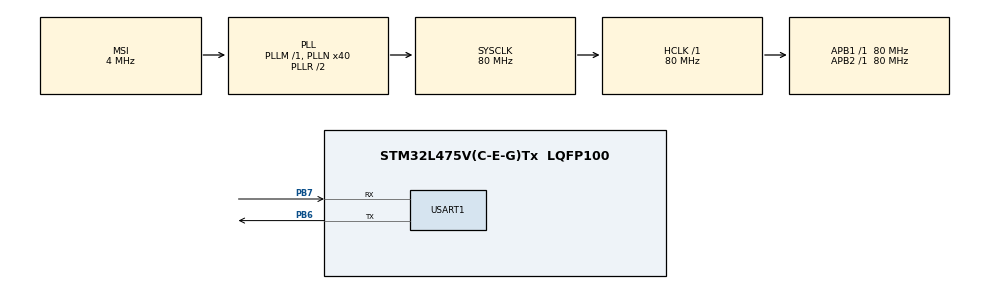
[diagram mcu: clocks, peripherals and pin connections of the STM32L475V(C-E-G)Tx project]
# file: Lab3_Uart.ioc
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ADC1.Channel-0\#ChannelRegularConversion=ADC_CHANNEL_TEMPSENSOR
ADC1.ClockPrescaler=ADC_CLOCK_ASYNC_DIV1
ADC1.ContinuousConvMode=DISABLE
ADC1.DMAContinuousRequests=DISABLE
ADC1.DataAlign=ADC_DATAALIGN_RIGHT
ADC1.DiscontinuousConvMode=DISABLE
ADC1.EOCSelection=ADC_EOC_SINGLE_CONV
ADC1.EnableAnalogWatchDog1=false
ADC1.EnableAnalogWatchDog2=false
ADC1.EnableAnalogWatchDog3=false
ADC1.EnableInjectedConversion=DISABLE
ADC1.EnableRegularConversion=ENABLE
ADC1.ExternalTrigConv=ADC_SOFTWARE_START
ADC1.ExternalTrigConvEdge=ADC_EXTERNALTRIGCONVEDGE_NONE
ADC1.LowPowerAutoWait=DISABLE
ADC1.NbrOfConversion=1
ADC1.NbrOfConversionFlag=1
ADC1.OffsetNumber-0\#ChannelRegularConversion=ADC_OFFSET_NONE
ADC1.Overrun=ADC_OVR_DATA_PRESERVED
ADC1.OversamplingMode=DISABLE
ADC1.Rank-0\#ChannelRegularConversion=1
ADC1.Resolution=ADC_RESOLUTION_10B
ADC1.SamplingTime-0\#ChannelRegularConversion=ADC_SAMPLETIME_2CYCLES_5
ADC1.ScanConvMode=ADC_SCAN_DISABLE
ADC1.master=1
Dma.Request0=USART1_RX
Dma.Request1=USART1_TX
Dma.USART1_RX.0.Direction=DMA_PERIPH_TO_MEMORY
Dma.USART1_RX.0.Instance=DMA1_Channel5
Dma.USART1_RX.0.MemDataAlignment=DMA_MDATAALIGN_HALFWORD
Dma.USART1_RX.0.MemInc=DMA_MINC_ENABLE
Dma.USART1_RX.0.Mode=DMA_NORMAL
Dma.USART1_RX.0.PeriphDataAlignment=DMA_PDATAALIGN_HALFWORD
Dma.USART1_RX.0.PeriphInc=DMA_PINC_DISABLE
Dma.USART1_RX.0.Priority=DMA_PRIORITY_LOW
Dma.USART1_TX.1.Direction=DMA_MEMORY_TO_PERIPH
Dma.USART1_TX.1.Instance=DMA1_Channel4
Dma.USART1_TX.1.MemDataAlignment=DMA_MDATAALIGN_HALFWORD
Dma.USART1_TX.1.MemInc=DMA_MINC_ENABLE
Dma.USART1_TX.1.Mode=DMA_NORMAL
Dma.USART1_TX.1.PeriphDataAlignment=DMA_PDATAALIGN_HALFWORD
Dma.USART1_TX.1.PeriphInc=DMA_PINC_DISABLE
Dma.USART1_TX.1.Priority=DMA_PRIORITY_LOW
Mcu.Family=STM32L4
Mcu.Name=STM32L475V(C-E-G)Tx
Mcu.Package=LQFP100
NVIC.DMA1_Channel4_IRQn=true\:0\:0\:false\:false\:true\:false
NVIC.DMA1_Channel5_IRQn=true\:0\:0\:false\:false\:true\:false
NVIC.PriorityGroup=NVIC_PRIORITYGROUP_4
NVIC.USART1_IRQn=true\:0\:0\:false\:false\:true\:true
PB6.Mode=Asynchronous
PB6.Signal=USART1_TX
PB7.Mode=Asynchronous
PB7.Signal=USART1_RX
ProjectManager.HeapSize=0x200
ProjectManager.StackSize=0x400
ProjectManager.TargetToolchain=MDK-ARM V5
RCC.ADCFreq_Value=64000000
RCC.AHBFreq_Value=80000000
RCC.APB1Freq_Value=80000000
RCC.APB1TimFreq_Value=80000000
RCC.APB2Freq_Value=80000000
RCC.APB2TimFreq_Value=80000000
RCC.CortexFreq_Value=80000000
RCC.HCLKFreq_Value=80000000
RCC.HSE_VALUE=8000000
RCC.HSI_VALUE=16000000
RCC.LSE_VALUE=32768
RCC.MSI_VALUE=4000000
RCC.PLLN=40
RCC.PLLSAI1N=32
RCC.SYSCLKFreq_VALUE=80000000
RCC.SYSCLKSource=RCC_SYSCLKSOURCE_PLLCLK
RCC.USBFreq_Value=64000000
RCC.VCOOutputFreq_Value=160000000
USART1.VirtualMode-Asynchronous=VM_ASYNC
USART1.WordLength=WORDLENGTH_8B
VP_ADC1_TempSens_Input.Mode=IN-TempSens
board=Lab3_Uart

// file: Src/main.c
/**
  ******************************************************************************
  * @file           : main.c
  * @brief          : Main program body
  ******************************************************************************
  ** This notice applies to any and all portions of this file
  * that are not between comment pairs USER CODE BEGIN and
  * USER CODE END. Other portions of this file, whether
  * inserted by the user or by software development tools
  * are owned by their respective copyright owners.
  *
  * COPYRIGHT(c) 2018 STMicroelectronics
  *
  * Redistribution and use in source and binary forms, with or without modification,
  * are permitted provided that the following conditions are met:
  *   1. Redistributions of source code must retain the above copyright notice,
  *      this list of conditions and the following disclaimer.
  *   2. Redistributions in binary form must reproduce the above copyright notice,
  *      this list of conditions and the following disclaimer in the documentation
  *      and/or other materials provided with the distribution.
  *   3. Neither the name of STMicroelectronics nor the names of its contributors
  *      may be used to endorse or promote products derived from this software
  *      without specific prior written permission.
  *
  * THIS SOFTWARE IS PROVIDED BY THE COPYRIGHT HOLDERS AND CONTRIBUTORS "AS IS"
  * AND ANY EXPRESS OR IMPLIED WARRANTIES, INCLUDING, BUT NOT LIMITED TO, THE
  * IMPLIED WARRANTIES OF MERCHANTABILITY AND FITNESS FOR A PARTICULAR PURPOSE ARE
  * DISCLAIMED. IN NO EVENT SHALL THE COPYRIGHT HOLDER OR CONTRIBUTORS BE LIABLE
  * FOR ANY DIRECT, INDIRECT, INCIDENTAL, SPECIAL, EXEMPLARY, OR CONSEQUENTIAL
  * DAMAGES (INCLUDING, BUT NOT LIMITED TO, PROCUREMENT OF SUBSTITUTE GOODS OR
  * SERVICES; LOSS OF USE, DATA, OR PROFITS; OR BUSINESS INTERRUPTION) HOWEVER
  * CAUSED AND ON ANY THEORY OF LIABILITY, WHETHER IN CONTRACT, STRICT LIABILITY,
  * OR TORT (INCLUDING NEGLIGENCE OR OTHERWISE) ARISING IN ANY WAY OUT OF THE USE
  * OF THIS SOFTWARE, EVEN IF ADVISED OF THE POSSIBILITY OF SUCH DAMAGE.
  *
  ******************************************************************************
  */
#include "main.h"
#include "stm32l4xx_hal.h"

ADC_HandleTypeDef hadc1;

UART_HandleTypeDef huart1;
DMA_HandleTypeDef hdma_usart1_rx;
DMA_HandleTypeDef hdma_usart1_tx;

/* USER CODE BEGIN PV */
/* Private variables ---------------------------------------------------------*/
	const int size = 7;
	char string[size] = {'s','t','a','r','t','\r','\n'};
	char input[1];
  char response[1] = {'y'};
  char ch[15] = {'j','o','b','s','\n', 'j','o','b','s','\n', 'j','o','b','s','\n'};
	char ADCValues[15];
	int ADCIndex = 0;
	int flag = 0;
	int txDone = 1;
	int temp = 0;
/* USER CODE END PV */

void SystemClock_Config(void);
static void MX_GPIO_Init(void);
static void MX_DMA_Init(void);
static void MX_ADC1_Init(void);
static void MX_USART1_UART_Init(void);

/* USER CODE BEGIN PFP */
/* Private function prototypes -----------------------------------------------*/

/* USER CODE END PFP */

/* USER CODE BEGIN 0 */
void ADC_Poll(void) {
	HAL_ADC_Start(&hadc1);
	if (HAL_ADC_PollForConversion(&hadc1, 2000) == HAL_OK) {
		int adcValue = HAL_ADC_GetValue(&hadc1);
		temp = __LL_ADC_CALC_TEMPERATURE(3500, adcValue, LL_ADC_RESOLUTION_10B);
		ADCIndex = ADCIndex % 15;
		sprintf(&ADCValues[ADCIndex++], "%d", temp / 10);
		sprintf(&ADCValues[ADCIndex++], "%d", temp % 10);
		ADCValues[ADCIndex++] = '\n';
		if (ADCIndex == 15) {
				HAL_UART_Transmit_DMA(&huart1, (uint8_t *)ADCValues, 15);
		}
	}
}
void HAL_UART_TxCpltCallback(UART_HandleTypeDef * handle) {
	HAL_UART_DMAStop(handle);
}

void HAL_SYSTICK_Callback(void) {
	flag = 1;
}

/* USER CODE END 0 */

int main(void)
{

  /* MCU Configuration----------------------------------------------------------*/

  /* Reset of all peripherals, Initializes the Flash interface and the Systick. */
  HAL_Init();

  /* Configure the system clock */
  SystemClock_Config();

  /* Initialize all configured peripherals */
  MX_GPIO_Init();
  MX_DMA_Init();
  MX_ADC1_Init();
  MX_USART1_UART_Init();
  /* USER CODE BEGIN 2 */

	//HAL_ADC_Start_IT(&hadc1);
	//HAL_NVIC_EnableIRQ(SysTick_IRQn);

	/* USER CODE END 2 */

  /* Infinite loop */
  while (1)
  {

  /* USER CODE BEGIN 3 */
		if (flag) {
			ADC_Poll();
			flag = 0;
		}
  }
  /* USER CODE END 3 */

}

void SystemClock_Config(void)
{

  RCC_OscInitTypeDef RCC_OscInitStruct;
  RCC_ClkInitTypeDef RCC_ClkInitStruct;
  RCC_PeriphCLKInitTypeDef PeriphClkInit;

    /**Initializes the CPU, AHB and APB busses clocks
    */
  RCC_OscInitStruct.OscillatorType = RCC_OSCILLATORTYPE_MSI;
  RCC_OscInitStruct.MSIState = RCC_MSI_ON;
  RCC_OscInitStruct.MSICalibrationValue = 0;
  RCC_OscInitStruct.MSIClockRange = RCC_MSIRANGE_6;
  RCC_OscInitStruct.PLL.PLLState = RCC_PLL_ON;
  RCC_OscInitStruct.PLL.PLLSource = RCC_PLLSOURCE_MSI;
  RCC_OscInitStruct.PLL.PLLM = 1;
  RCC_OscInitStruct.PLL.PLLN = 40;
  RCC_OscInitStruct.PLL.PLLP = RCC_PLLP_DIV7;
  RCC_OscInitStruct.PLL.PLLQ = RCC_PLLQ_DIV2;
  RCC_OscInitStruct.PLL.PLLR = RCC_PLLR_DIV2;
  if (HAL_RCC_OscConfig(&RCC_OscInitStruct) != HAL_OK)
  {
    _Error_Handler(__FILE__, __LINE__);
  }

    /**Initializes the CPU, AHB and APB busses clocks
    */
  RCC_ClkInitStruct.ClockType = RCC_CLOCKTYPE_HCLK|RCC_CLOCKTYPE_SYSCLK
                              |RCC_CLOCKTYPE_PCLK1|RCC_CLOCKTYPE_PCLK2;
  RCC_ClkInitStruct.SYSCLKSource = RCC_SYSCLKSOURCE_PLLCLK;
  RCC_ClkInitStruct.AHBCLKDivider = RCC_SYSCLK_DIV1;
  RCC_ClkInitStruct.APB1CLKDivider = RCC_HCLK_DIV1;
  RCC_ClkInitStruct.APB2CLKDivider = RCC_HCLK_DIV1;

  if (HAL_RCC_ClockConfig(&RCC_ClkInitStruct, FLASH_LATENCY_4) != HAL_OK)
  {
    _Error_Handler(__FILE__, __LINE__);
  }

  PeriphClkInit.PeriphClockSelection = RCC_PERIPHCLK_USART1|RCC_PERIPHCLK_ADC;
  PeriphClkInit.Usart1ClockSelection = RCC_USART1CLKSOURCE_PCLK2;
  PeriphClkInit.AdcClockSelection = RCC_ADCCLKSOURCE_PLLSAI1;
  PeriphClkInit.PLLSAI1.PLLSAI1Source = RCC_PLLSOURCE_MSI;
  PeriphClkInit.PLLSAI1.PLLSAI1M = 1;
  PeriphClkInit.PLLSAI1.PLLSAI1N = 32;
  PeriphClkInit.PLLSAI1.PLLSAI1P = RCC_PLLP_DIV7;
  PeriphClkInit.PLLSAI1.PLLSAI1Q = RCC_PLLQ_DIV2;
  PeriphClkInit.PLLSAI1.PLLSAI1R = RCC_PLLR_DIV2;
  PeriphClkInit.PLLSAI1.PLLSAI1ClockOut = RCC_PLLSAI1_ADC1CLK;
  if (HAL_RCCEx_PeriphCLKConfig(&PeriphClkInit) != HAL_OK)
  {
    _Error_Handler(__FILE__, __LINE__);
  }

    /**Configure the main internal regulator output voltage
    */
  if (HAL_PWREx_ControlVoltageScaling(PWR_REGULATOR_VOLTAGE_SCALE1) != HAL_OK)
  {
    _Error_Handler(__FILE__, __LINE__);
  }

    /**Configure the Systick interrupt time
    */
  HAL_SYSTICK_Config(HAL_RCC_GetHCLKFreq()/1000);

    /**Configure the Systick
    */
  HAL_SYSTICK_CLKSourceConfig(SYSTICK_CLKSOURCE_HCLK);

  /* SysTick_IRQn interrupt configuration */
  HAL_NVIC_SetPriority(SysTick_IRQn, 0, 0);
}

/* ADC1 init function */
static void MX_ADC1_Init(void)
{

  ADC_MultiModeTypeDef multimode;
  ADC_ChannelConfTypeDef sConfig;

    /**Common config
    */
  hadc1.Instance = ADC1;
  hadc1.Init.ClockPrescaler = ADC_CLOCK_ASYNC_DIV1;
  hadc1.Init.Resolution = ADC_RESOLUTION_10B;
  hadc1.Init.DataAlign = ADC_DATAALIGN_RIGHT;
  hadc1.Init.ScanConvMode = ADC_SCAN_DISABLE;
  hadc1.Init.EOCSelection = ADC_EOC_SINGLE_CONV;
  hadc1.Init.LowPowerAutoWait = DISABLE;
  hadc1.Init.ContinuousConvMode = DISABLE;
  hadc1.Init.NbrOfConversion = 1;
  hadc1.Init.DiscontinuousConvMode = DISABLE;
  hadc1.Init.NbrOfDiscConversion = 1;
  hadc1.Init.ExternalTrigConv = ADC_SOFTWARE_START;
  hadc1.Init.ExternalTrigConvEdge = ADC_EXTERNALTRIGCONVEDGE_NONE;
  hadc1.Init.DMAContinuousRequests = DISABLE;
  hadc1.Init.Overrun = ADC_OVR_DATA_PRESERVED;
  hadc1.Init.OversamplingMode = DISABLE;
  if (HAL_ADC_Init(&hadc1) != HAL_OK)
  {
    _Error_Handler(__FILE__, __LINE__);
  }

    /**Configure the ADC multi-mode
    */
  multimode.Mode = ADC_MODE_INDEPENDENT;
  if (HAL_ADCEx_MultiModeConfigChannel(&hadc1, &multimode) != HAL_OK)
  {
    _Error_Handler(__FILE__, __LINE__);
  }

    /**Configure Regular Channel
    */
  sConfig.Channel = ADC_CHANNEL_TEMPSENSOR;
  sConfig.Rank = ADC_REGULAR_RANK_1;
  sConfig.SamplingTime = ADC_SAMPLETIME_47CYCLES_5;
  sConfig.SingleDiff = ADC_SINGLE_ENDED;
  sConfig.OffsetNumber = ADC_OFFSET_NONE;
  sConfig.Offset = 0;
  if (HAL_ADC_ConfigChannel(&hadc1, &sConfig) != HAL_OK)
  {
    _Error_Handler(__FILE__, __LINE__);
  }

}

/* USART1 init function */
static void MX_USART1_UART_Init(void)
{

  huart1.Instance = USART1;
  huart1.Init.BaudRate = 115200;
  huart1.Init.WordLength = UART_WORDLENGTH_8B;
  huart1.Init.StopBits = UART_STOPBITS_1;
  huart1.Init.Parity = UART_PARITY_NONE;
  huart1.Init.Mode = UART_MODE_TX_RX;
  huart1.Init.HwFlowCtl = UART_HWCONTROL_NONE;
  huart1.Init.OverSampling = UART_OVERSAMPLING_16;
  huart1.Init.OneBitSampling = UART_ONE_BIT_SAMPLE_DISABLE;
  huart1.AdvancedInit.AdvFeatureInit = UART_ADVFEATURE_NO_INIT;
  if (HAL_UART_Init(&huart1) != HAL_OK)
  {
    _Error_Handler(__FILE__, __LINE__);
  }

}

static void MX_DMA_Init(void)
{
  /* DMA controller clock enable */
  __HAL_RCC_DMA1_CLK_ENABLE();

  /* DMA interrupt init */
  /* DMA1_Channel4_IRQn interrupt configuration */
  HAL_NVIC_SetPriority(DMA1_Channel4_IRQn, 0, 0);
  HAL_NVIC_EnableIRQ(DMA1_Channel4_IRQn);
  /* DMA1_Channel5_IRQn interrupt configuration */
  HAL_NVIC_SetPriority(DMA1_Channel5_IRQn, 0, 0);
  HAL_NVIC_EnableIRQ(DMA1_Channel5_IRQn);

}

/** Pinout Configuration
*/
static void MX_GPIO_Init(void)
{

  /* GPIO Ports Clock Enable */
  __HAL_RCC_GPIOB_CLK_ENABLE();

}

void _Error_Handler(char *file, int line)
{
  while(1)
  {
  }
}

/************************ (C) COPYRIGHT STMicroelectronics *****END OF FILE****/
